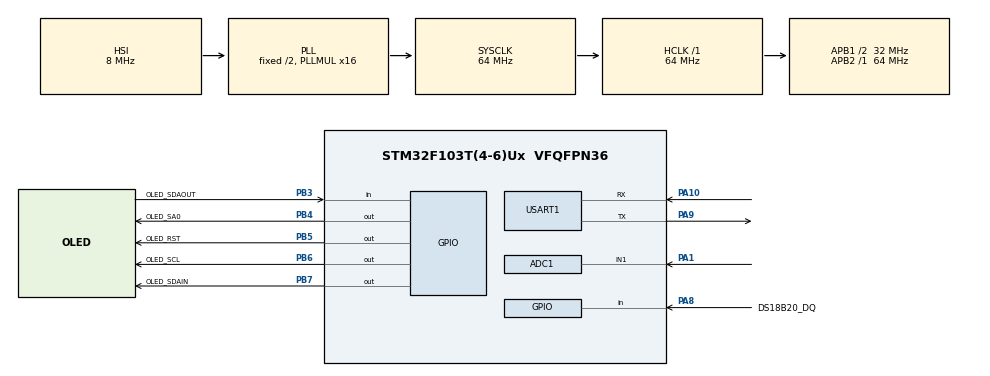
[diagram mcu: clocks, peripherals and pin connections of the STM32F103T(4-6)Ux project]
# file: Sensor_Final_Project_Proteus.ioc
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ADC1.Channel-0\#ChannelRegularConversion=ADC_CHANNEL_1
ADC1.NbrOfConversionFlag=1
ADC1.Rank-0\#ChannelRegularConversion=1
ADC1.SamplingTime-0\#ChannelRegularConversion=ADC_SAMPLETIME_239CYCLES_5
ADC1.master=1
Mcu.Family=STM32F1
Mcu.Name=STM32F103T(4-6)Ux
Mcu.Package=VFQFPN36
NVIC.PriorityGroup=NVIC_PRIORITYGROUP_4
NVIC.TIM2_IRQn=true\:0\:0\:false\:false\:true\:true\:true\:true
PA1.Signal=ADCx_IN1
PA10.Mode=Asynchronous
PA10.Signal=USART1_RX
PA13.Mode=Serial_Wire
PA13.Signal=SYS_JTMS-SWDIO
PA14.Mode=Serial_Wire
PA14.Signal=SYS_JTCK-SWCLK
PA8.GPIO_Label=DS18B20_DQ
PA8.Signal=GPIO_Input
PA9.Mode=Asynchronous
PA9.Signal=USART1_TX
PB3.GPIO_Label=OLED_SDAOUT
PB3.GPIO_PuPd=GPIO_PULLUP
PB3.Signal=GPIO_Input
PB4.GPIO_Label=OLED_SA0
PB4.GPIO_Speed=GPIO_SPEED_FREQ_HIGH
PB4.Signal=GPIO_Output
PB5.GPIO_Label=OLED_RST
PB5.GPIO_Speed=GPIO_SPEED_FREQ_HIGH
PB5.PinState=GPIO_PIN_SET
PB5.Signal=GPIO_Output
PB6.GPIO_Label=OLED_SCL
PB6.GPIO_Speed=GPIO_SPEED_FREQ_HIGH
PB6.PinState=GPIO_PIN_SET
PB6.Signal=GPIO_Output
PB7.GPIO_Label=OLED_SDAIN
PB7.GPIO_Speed=GPIO_SPEED_FREQ_HIGH
PB7.PinState=GPIO_PIN_SET
PB7.Signal=GPIO_Output
ProjectManager.HeapSize=0x200
ProjectManager.StackSize=0x400
ProjectManager.TargetToolchain=STM32CubeIDE
RCC.ADCPresc=RCC_ADCPCLK2_DIV6
RCC.AHBFreq_Value=64000000
RCC.APB1CLKDivider=RCC_HCLK_DIV2
RCC.APB1Freq_Value=32000000
RCC.APB1TimFreq_Value=64000000
RCC.APB2Freq_Value=64000000
RCC.APB2TimFreq_Value=64000000
RCC.HCLKFreq_Value=64000000
RCC.PLLMUL=RCC_PLL_MUL16
RCC.SYSCLKFreq_VALUE=64000000
RCC.SYSCLKSource=RCC_SYSCLKSOURCE_PLLCLK
RCC.USBFreq_Value=64000000
SH.ADCx_IN1.0=ADC1_IN1,IN1
TIM2.Period=10000 - 1
TIM2.Prescaler=6400 - 1
USART1.VirtualMode=VM_ASYNC
VP_TIM2_VS_ClockSourceINT.Mode=Internal
board=custom

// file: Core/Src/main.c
/* USER CODE BEGIN Header */
/**
  ******************************************************************************
  * @file           : main.c
  * @brief          : Main program body
  ******************************************************************************
  * @attention
  *
  * Copyright (c) 2026 STMicroelectronics.
  * All rights reserved.
  *
  * This software is licensed under terms that can be found in the LICENSE file
  * in the root directory of this software component.
  * If no LICENSE file comes with this software, it is provided AS-IS.
  *
  ******************************************************************************
  */
/* USER CODE END Header */
#include "main.h"
#include "adc.h"
#include "tim.h"
#include "usart.h"
#include "gpio.h"

/* USER CODE BEGIN Includes */
#include "app_task.h"

/* USER CODE END Includes */

/* USER CODE BEGIN PV */
volatile uint8_t g_task_1s_flag = 0;

/* USER CODE END PV */

void SystemClock_Config(void);

int main(void)
{

  /* MCU Configuration--------------------------------------------------------*/

  /* Reset of all peripherals, Initializes the Flash interface and the Systick. */
  HAL_Init();

  /* Configure the system clock */
  SystemClock_Config();

  /* Initialize all configured peripherals */
  MX_GPIO_Init();
  MX_ADC1_Init();
  MX_TIM2_Init();
  MX_USART1_UART_Init();
  /* USER CODE BEGIN 2 */
  const char msg1[] = "pH Meter Ready\r\n";
  HAL_UART_Transmit(&huart1, (uint8_t *)msg1, sizeof(msg1) - 1, 100);
  APP_UserInit();
  HAL_TIM_Base_Start_IT(&htim2);

//  APP_UserInit();
 // HAL_TIM_Base_Start_IT(&htim2);
//  const char *boot_msg = "BOOT OK\r\n";
//  HAL_UART_Transmit(&huart1, (uint8_t *)boot_msg, 9, 100);

  /* USER CODE END 2 */

  /* Infinite loop */
  while (1)
  {

    /* USER CODE BEGIN 3 */
    if (g_task_1s_flag)
    {
      g_task_1s_flag = 0;
      APP_Task1s();
    }
  }
  /* USER CODE END 3 */
}

void SystemClock_Config(void)
{
  RCC_OscInitTypeDef RCC_OscInitStruct = {0};
  RCC_ClkInitTypeDef RCC_ClkInitStruct = {0};
  RCC_PeriphCLKInitTypeDef PeriphClkInit = {0};

  /** Initializes the RCC Oscillators according to the specified parameters
  * in the RCC_OscInitTypeDef structure.
  */
  RCC_OscInitStruct.OscillatorType = RCC_OSCILLATORTYPE_HSI;
  RCC_OscInitStruct.HSIState = RCC_HSI_ON;
  RCC_OscInitStruct.HSICalibrationValue = RCC_HSICALIBRATION_DEFAULT;
  RCC_OscInitStruct.PLL.PLLState = RCC_PLL_ON;
  RCC_OscInitStruct.PLL.PLLSource = RCC_PLLSOURCE_HSI_DIV2;
  RCC_OscInitStruct.PLL.PLLMUL = RCC_PLL_MUL16;
  if (HAL_RCC_OscConfig(&RCC_OscInitStruct) != HAL_OK)
  {
    Error_Handler();
  }

  /** Initializes the CPU, AHB and APB buses clocks
  */
  RCC_ClkInitStruct.ClockType = RCC_CLOCKTYPE_HCLK|RCC_CLOCKTYPE_SYSCLK
                              |RCC_CLOCKTYPE_PCLK1|RCC_CLOCKTYPE_PCLK2;
  RCC_ClkInitStruct.SYSCLKSource = RCC_SYSCLKSOURCE_PLLCLK;
  RCC_ClkInitStruct.AHBCLKDivider = RCC_SYSCLK_DIV1;
  RCC_ClkInitStruct.APB1CLKDivider = RCC_HCLK_DIV2;
  RCC_ClkInitStruct.APB2CLKDivider = RCC_HCLK_DIV1;

  if (HAL_RCC_ClockConfig(&RCC_ClkInitStruct, FLASH_LATENCY_2) != HAL_OK)
  {
    Error_Handler();
  }
  PeriphClkInit.PeriphClockSelection = RCC_PERIPHCLK_ADC;
  PeriphClkInit.AdcClockSelection = RCC_ADCPCLK2_DIV6;
  if (HAL_RCCEx_PeriphCLKConfig(&PeriphClkInit) != HAL_OK)
  {
    Error_Handler();
  }
}

/* USER CODE BEGIN 4 */
/*void HAL_TIM_PeriodElapsedCallback(TIM_HandleTypeDef *htim)
{
    if (htim->Instance == TIM2)
    {
        APP_Timer1sISR();
        g_task_1s_flag = 1;
    }
}*/
void HAL_TIM_PeriodElapsedCallback(TIM_HandleTypeDef *htim)
{
    if (htim->Instance == TIM2)
    {
        APP_Timer1sISR();
        g_task_1s_flag = 1;
    }
}
/* USER CODE END 4 */

void Error_Handler(void)
{
  __disable_irq();
  while (1)
  {
  }
}
